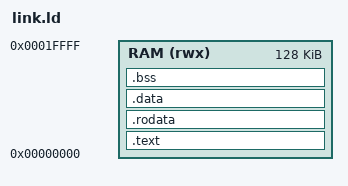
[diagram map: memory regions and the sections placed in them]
ENTRY(_start)
MEMORY { RAM (rwx) : ORIGIN = 0, LENGTH = 128K }
SECTIONS {
    .text : { *(.text.start) *(.text*) } > RAM
    .rodata : { *(.rodata*) *(.srodata*) } > RAM
    .data : { *(.data*) *(.sdata*) } > RAM
    .bss (NOLOAD) : {
        . = ALIGN(4); __bss_start = .;
        *(.bss*) *(.sbss*) *(COMMON)
        . = ALIGN(4); __bss_end = .;
    } > RAM
    /DISCARD/ : { *(.comment) *(.riscv.attributes) }
}
